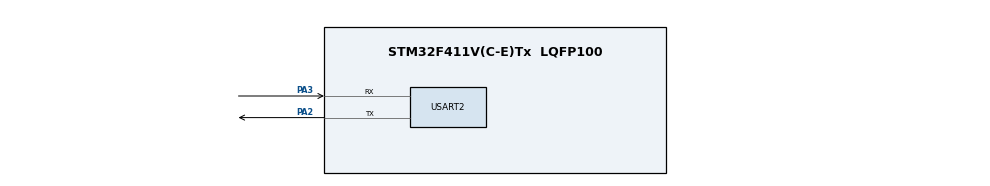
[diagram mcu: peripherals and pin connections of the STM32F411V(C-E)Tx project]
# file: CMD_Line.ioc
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Mcu.Family=STM32F4
Mcu.Name=STM32F411V(C-E)Tx
Mcu.Package=LQFP100
NVIC.PriorityGroup=NVIC_PRIORITYGROUP_4
NVIC.USART2_IRQn=true\:1\:0\:true\:false\:true\:true\:true\:true
PA13.Mode=Serial_Wire
PA13.Signal=SYS_JTMS-SWDIO
PA14.Mode=Serial_Wire
PA14.Signal=SYS_JTCK-SWCLK
PA2.Mode=Asynchronous
PA2.Signal=USART2_TX
PA3.Mode=Asynchronous
PA3.Signal=USART2_RX
PH0\ -\ OSC_IN.Mode=HSE-External-Oscillator
PH0\ -\ OSC_IN.Signal=RCC_OSC_IN
PH1\ -\ OSC_OUT.Mode=HSE-External-Oscillator
PH1\ -\ OSC_OUT.Signal=RCC_OSC_OUT
ProjectManager.HeapSize=0x200
ProjectManager.StackSize=0x400
ProjectManager.TargetToolchain=STM32CubeIDE
RCC.48MHZClocksFreq_Value=32000000
RCC.AHBCLKDivider=RCC_SYSCLK_DIV4
RCC.AHBFreq_Value=16000000
RCC.APB1Freq_Value=16000000
RCC.APB1TimFreq_Value=16000000
RCC.APB2Freq_Value=16000000
RCC.APB2TimFreq_Value=16000000
RCC.CortexFreq_Value=16000000
RCC.HCLKFreq_Value=16000000
RCC.HSE_VALUE=8000000
RCC.HSI_VALUE=16000000
RCC.LSE_VALUE=32768
RCC.PLLM=8
RCC.PLLN=64
RCC.SYSCLKFreq_VALUE=64000000
RCC.SYSCLKSource=RCC_SYSCLKSOURCE_PLLCLK
RCC.VCOOutputFreq_Value=128000000
USART2.VirtualMode=VM_ASYNC
board=custom

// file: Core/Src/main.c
/* USER CODE BEGIN Header */
/**
  ******************************************************************************
  * @file           : main.c
  * @brief          : Main program body
  ******************************************************************************
  * @attention
  *
  * Copyright (c) 2024 STMicroelectronics.
  * All rights reserved.
  *
  * This software is licensed under terms that can be found in the LICENSE file
  * in the root directory of this software component.
  * If no LICENSE file comes with this software, it is provided AS-IS.
  *
  ******************************************************************************
  */
/* USER CODE END Header */
#include "main.h"

/* USER CODE BEGIN Includes */
#include "uart.h"
/* USER CODE END Includes */

/* USER CODE BEGIN PV */
uart_cfg_t uart_cfg_2;
/* USER CODE END PV */

void SystemClock_Config(void);
static void MX_GPIO_Init(void);
static void MX_USART2_UART_Init(void);

int main(void)
{

  /* MCU Configuration--------------------------------------------------------*/

  /* Reset of all peripherals, Initializes the Flash interface and the Systick. */
  LL_APB2_GRP1_EnableClock(LL_APB2_GRP1_PERIPH_SYSCFG);
  LL_APB1_GRP1_EnableClock(LL_APB1_GRP1_PERIPH_PWR);

  /* System interrupt init*/
  NVIC_SetPriorityGrouping(NVIC_PRIORITYGROUP_4);

  /* SysTick_IRQn interrupt configuration */
  NVIC_SetPriority(SysTick_IRQn, NVIC_EncodePriority(NVIC_GetPriorityGrouping(),15, 0));

  /* Configure the system clock */
  SystemClock_Config();

  /* Initialize all configured peripherals */
  MX_GPIO_Init();
  MX_USART2_UART_Init();
  /* USER CODE BEGIN 2 */
  UARTConfig(&uart_cfg_2, USART2, USART2_IRQn, true);
  /* USER CODE END 2 */

  /* Infinite loop */
  /* USER CODE BEGIN WHILE */
  vTaskStartScheduler();
  while (1)
  {
    /* USER CODE END WHILE */

  }
}

void SystemClock_Config(void)
{
  LL_FLASH_SetLatency(LL_FLASH_LATENCY_0);
  while(LL_FLASH_GetLatency()!= LL_FLASH_LATENCY_0)
  {
  }
  LL_PWR_SetRegulVoltageScaling(LL_PWR_REGU_VOLTAGE_SCALE1);
  LL_RCC_HSI_SetCalibTrimming(16);
  LL_RCC_HSI_Enable();

   /* Wait till HSI is ready */
  while(LL_RCC_HSI_IsReady() != 1)
  {

  }
  LL_RCC_PLL_ConfigDomain_SYS(LL_RCC_PLLSOURCE_HSI, LL_RCC_PLLM_DIV_8, 64, LL_RCC_PLLP_DIV_2);
  LL_RCC_PLL_Enable();

   /* Wait till PLL is ready */
  while(LL_RCC_PLL_IsReady() != 1)
  {

  }
  while (LL_PWR_IsActiveFlag_VOS() == 0)
  {
  }
  LL_RCC_SetAHBPrescaler(LL_RCC_SYSCLK_DIV_4);
  LL_RCC_SetAPB1Prescaler(LL_RCC_APB1_DIV_1);
  LL_RCC_SetAPB2Prescaler(LL_RCC_APB2_DIV_1);
  LL_RCC_SetSysClkSource(LL_RCC_SYS_CLKSOURCE_PLL);

   /* Wait till System clock is ready */
  while(LL_RCC_GetSysClkSource() != LL_RCC_SYS_CLKSOURCE_STATUS_PLL)
  {

  }
  LL_Init1msTick(16000000);
  LL_SetSystemCoreClock(16000000);
  LL_RCC_SetTIMPrescaler(LL_RCC_TIM_PRESCALER_TWICE);
}

static void MX_USART2_UART_Init(void)
{

  LL_USART_InitTypeDef USART_InitStruct = {0};

  LL_GPIO_InitTypeDef GPIO_InitStruct = {0};

  /* Peripheral clock enable */
  LL_APB1_GRP1_EnableClock(LL_APB1_GRP1_PERIPH_USART2);

  LL_AHB1_GRP1_EnableClock(LL_AHB1_GRP1_PERIPH_GPIOA);
  /**USART2 GPIO Configuration
  PA2   ------> USART2_TX
  PA3   ------> USART2_RX
  */
  GPIO_InitStruct.Pin = LL_GPIO_PIN_2|LL_GPIO_PIN_3;
  GPIO_InitStruct.Mode = LL_GPIO_MODE_ALTERNATE;
  GPIO_InitStruct.Speed = LL_GPIO_SPEED_FREQ_VERY_HIGH;
  GPIO_InitStruct.OutputType = LL_GPIO_OUTPUT_PUSHPULL;
  GPIO_InitStruct.Pull = LL_GPIO_PULL_NO;
  GPIO_InitStruct.Alternate = LL_GPIO_AF_7;
  LL_GPIO_Init(GPIOA, &GPIO_InitStruct);

  /* USART2 interrupt Init */
  NVIC_SetPriority(USART2_IRQn, NVIC_EncodePriority(NVIC_GetPriorityGrouping(),1, 0));
  NVIC_EnableIRQ(USART2_IRQn);

  USART_InitStruct.BaudRate = 115200;
  USART_InitStruct.DataWidth = LL_USART_DATAWIDTH_8B;
  USART_InitStruct.StopBits = LL_USART_STOPBITS_1;
  USART_InitStruct.Parity = LL_USART_PARITY_NONE;
  USART_InitStruct.TransferDirection = LL_USART_DIRECTION_TX_RX;
  USART_InitStruct.HardwareFlowControl = LL_USART_HWCONTROL_NONE;
  USART_InitStruct.OverSampling = LL_USART_OVERSAMPLING_16;
  LL_USART_Init(USART2, &USART_InitStruct);
  LL_USART_ConfigAsyncMode(USART2);
  LL_USART_Enable(USART2);

}

static void MX_GPIO_Init(void)
{

  /* GPIO Ports Clock Enable */
  LL_AHB1_GRP1_EnableClock(LL_AHB1_GRP1_PERIPH_GPIOH);
  LL_AHB1_GRP1_EnableClock(LL_AHB1_GRP1_PERIPH_GPIOA);

}

void Error_Handler(void)
{
  __disable_irq();
  while (1)
  {
  }
}
